# RK3399-AP register map
File version: 1
CPU: CA7 r0p1, little endian, MPU, FPU, I-cache, D-cache, VTOR, 4 interrupt priority bits, 32 interrupts
Registers are 32-bit, read-write, reset 0x0 unless marked. A register's access mark holds for its fields unless they carry their own. Offsets are from the block's base; [hi:lo] are bit positions; {n}, {i} and the like mark numbered series.

## PMUSGRF
Base 0xFF330000
{0x0+4i} ddr_rgn_con{i} access not given (i=0..21)
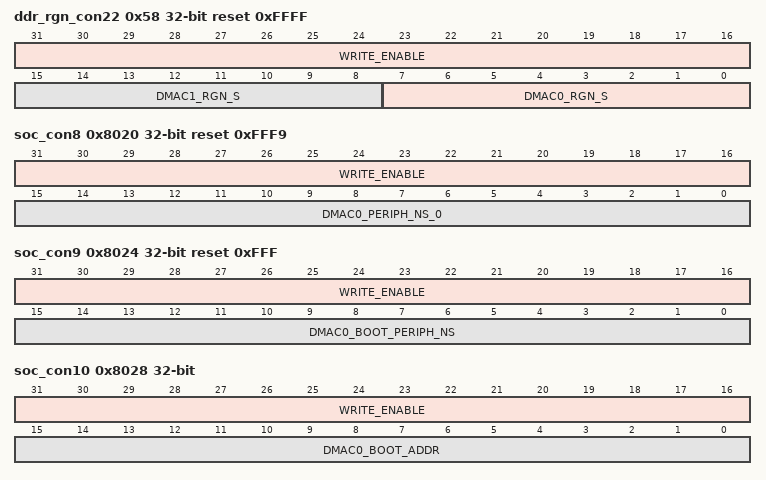
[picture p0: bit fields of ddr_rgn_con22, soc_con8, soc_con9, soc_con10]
0x58 ddr_rgn_con22 access per field reset 0xFFFF
  [31:16] WRITE_ENABLE wo
  [15:8] DMAC1_RGN_S rw — 1 indicates secure, 0 indicates non-secure.
  [7:0] DMAC0_RGN_S rw — 1 indicates secure, 0 indicates non-secure.
{0x0+4i} ddr_rgn_con{i} access not given (i=23..34)
0x8020 soc_con8 access per field reset 0xFFF9
  [31:16] WRITE_ENABLE wo
  [15:0] DMAC0_PERIPH_NS_0 rw — CFG_NS
0x8024 soc_con9 access per field reset 0xFFF
  [31:16] WRITE_ENABLE wo
  [15:0] DMAC0_BOOT_PERIPH_NS rw — 0 indicates secure, 1 indicates non-secure.
0x8028 soc_con10 access per field
  [31:16] WRITE_ENABLE wo
  [15:0] DMAC0_BOOT_ADDR rw — 0 indicates secure, 1 indicates non-secure.
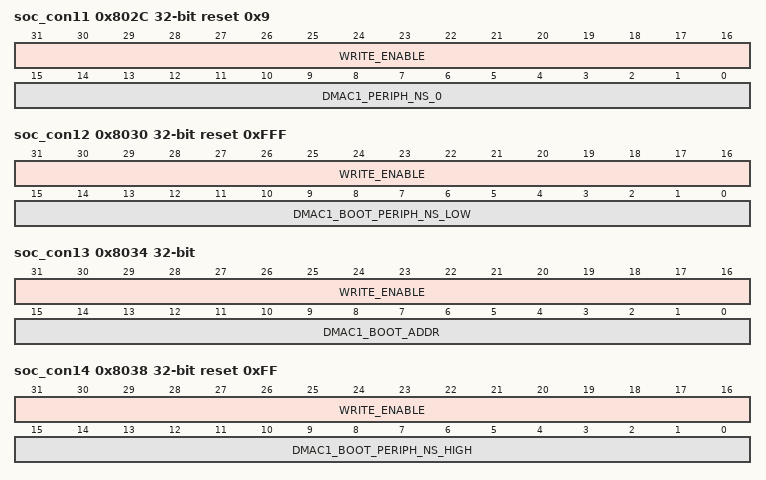
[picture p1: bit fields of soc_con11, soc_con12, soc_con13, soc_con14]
0x802C soc_con11 access per field reset 0x9
  [31:16] WRITE_ENABLE wo
  [15:0] DMAC1_PERIPH_NS_0 rw — (CFG)
0x8030 soc_con12 access per field reset 0xFFF
  [31:16] WRITE_ENABLE wo
  [15:0] DMAC1_BOOT_PERIPH_NS_LOW rw — 0 indicates secure, 1 indicates non-secure.
0x8034 soc_con13 access per field
  [31:16] WRITE_ENABLE wo
  [15:0] DMAC1_BOOT_ADDR rw — 0 indicates secure, 1 indicates non-secure.
0x8038 soc_con14 access per field reset 0xFF
  [31:16] WRITE_ENABLE wo
  [15:0] DMAC1_BOOT_PERIPH_NS_HIGH rw — 0 indicates secure, 1 indicates non-secure.
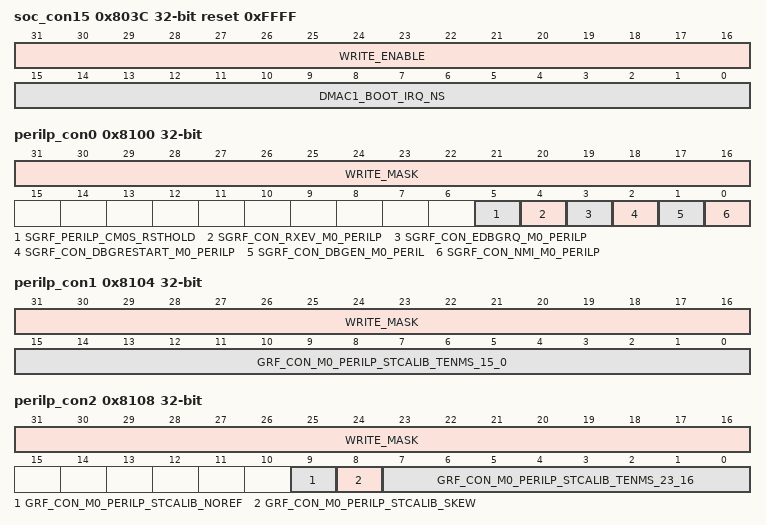
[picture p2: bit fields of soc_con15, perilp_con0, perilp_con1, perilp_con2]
0x803C soc_con15 access per field reset 0xFFFF
  [31:16] WRITE_ENABLE wo
  [15:0] DMAC1_BOOT_IRQ_NS rw — 0 indicates secure, 1 indicates non-secure.
{0x8000+4i} soc_con{i} access not given (i=19..22)
0x8100 perilp_con0 access per field
  [31:16] WRITE_MASK wo
  [5] SGRF_PERILP_CM0S_RSTHOLD rw — Reset hold control
  [4] SGRF_CON_RXEV_M0_PERILP rw — A HIGH level on this input causes the architecture defined Event Register to be set in the Cortex-M0 processor. This causes a WFE instruction to complete. It also awakens the processor if it is sleeping as the result of encountering a WFE instruction when the Event Register is clear.
  [3] SGRF_CON_EDBGRQ_M0_PERILP rw — External debug request
  [2] SGRF_CON_DBGRESTART_M0_PERILP rw — External restart request
  [1] SGRF_CON_DBGEN_M0_PERIL rw — Serial Wire Debug enable
  [0] SGRF_CON_NMI_M0_PERILP rw — Non maskable interrupt
0x8104 perilp_con1 access per field
  [31:16] WRITE_MASK wo
  [15:0] GRF_CON_M0_PERILP_STCALIB_TENMS_15_0 rw — See also: grf_con_m0_perilp_stcalib_tenms_23_16
0x8108 perilp_con2 access per field
  [31:16] WRITE_MASK wo
  [9] GRF_CON_M0_PERILP_STCALIB_NOREF rw — Indicates that no alternative reference clock source has been integrated. Tie HIGH if STCLKEN has been tied off.
  [8] GRF_CON_M0_PERILP_STCALIB_SKEW rw — Tie this LOW if the system timer clock, the external reference clock, or SCLK as indicated by STCALIB[25] (grf_con_m0_perilp_stcalib_noref), can guarantee an exact multiple of 10ms. Otherwise, tie this signal HIGH.
  [7:0] GRF_CON_M0_PERILP_STCALIB_TENMS_23_16 rw — See also: grf_con_m0_perilp_stcalib_tenms_15_0
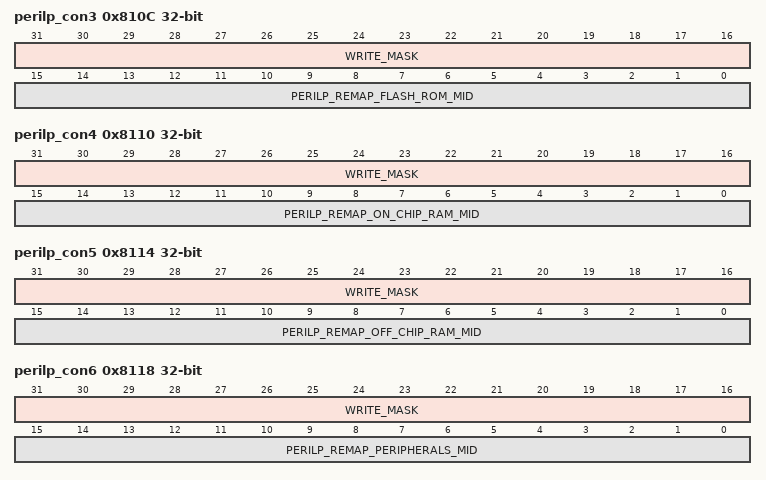
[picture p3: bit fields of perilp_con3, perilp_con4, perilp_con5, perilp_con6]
0x810C perilp_con3 access per field
  [31:16] WRITE_MASK wo
  [15:0] PERILP_REMAP_FLASH_ROM_MID rw — middle 16 bits of 0x00000000-0x1FFFFFFF remap
0x8110 perilp_con4 access per field
  [31:16] WRITE_MASK wo
  [15:0] PERILP_REMAP_ON_CHIP_RAM_MID rw — middle 16 bits of 0x20000000-0x3FFFFFFF remap
0x8114 perilp_con5 access per field
  [31:16] WRITE_MASK wo
  [15:0] PERILP_REMAP_OFF_CHIP_RAM_MID rw — Middle 16 bits of 0x60000000-0x7FFFFFFF and 0x80000000-0x9FFFFFFF memory regions.
0x8118 perilp_con6 access per field
  [31:16] WRITE_MASK wo
  [15:0] PERILP_REMAP_PERIPHERALS_MID rw — middle 16 bits of 0xA0000000-0xDFFFFFFF remap.
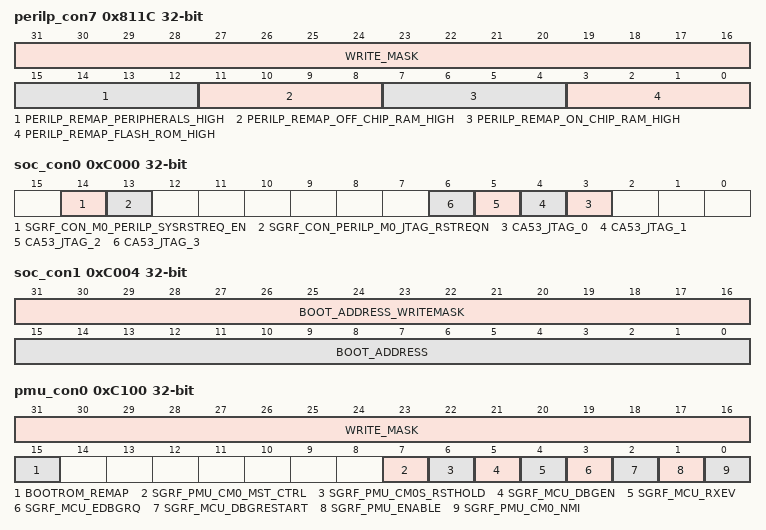
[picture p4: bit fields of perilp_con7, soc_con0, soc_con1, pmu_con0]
0x811C perilp_con7 access per field
  [31:16] WRITE_MASK wo
  [15:12] PERILP_REMAP_PERIPHERALS_HIGH rw — top 4 bits of 0xA0000000-0xDFFFFFFF remap
  [11:8] PERILP_REMAP_OFF_CHIP_RAM_HIGH rw — Top 4 bits of 0x60000000-0x7FFFFFFF and 0x80000000-0x9FFFFFFF memory regions.
  [7:4] PERILP_REMAP_ON_CHIP_RAM_HIGH rw — top 4 bits of 0x20000000-0x3FFFFFFF remap
  [3:0] PERILP_REMAP_FLASH_ROM_HIGH rw — top 4 bits of 0x00000000-0x1FFFFFFF remap
0x8120 perilp_con8
  [7:0] GRF_CON_M0_PERILP_IRQLATENCY — Minimum number of cycles between an interrupt that becomes pended in the NVIC, and the vector fetch for that interrupt being issued
0x8140 perilp_status access not given
0xC000 soc_con0
  [14] SGRF_CON_M0_PERILP_SYSRSTREQ_EN — Enable for SYSRESETREQ
  [13] SGRF_CON_PERILP_M0_JTAG_RSTREQN — Always be 0
  [n+3] CA53_JTAG_{n} (n=0..3) — CA53 JTAG
0xC004 soc_con1 access per field
  [31:16] BOOT_ADDRESS_WRITEMASK wo
  [15:0] BOOT_ADDRESS rw — Warm boot address for CPU. Could be DMAC0 BOOT ADDR
0xC100 pmu_con0 access per field
  [31:16] WRITE_MASK wo
  [15] BOOTROM_REMAP rw — Remaps 0xFFFF0000 to BOOTROM or INTMEM0. From page 29. **NOTE**: might be bootrom_remap_shadow instead.
  [7] SGRF_PMU_CM0_MST_CTRL rw — Master security attribute
  [6] SGRF_PMU_CM0S_RSTHOLD rw — Reset hold control
  [5] SGRF_MCU_DBGEN rw — Serial Wire Debug enable
  [4] SGRF_MCU_RXEV rw — A HIGH level on this input causes the architecture defined Event Register to be set in the Cortex-M0 processor. This causes a WFE instruction to complete. It also awakens the processor if it is sleeping as the result of encountering a WFE instruction when the Event Register is clear.
  [3] SGRF_MCU_EDBGRQ rw — External debug request
  [2] SGRF_MCU_DBGRESTART rw — External restart request
  [1] SGRF_PMU_ENABLE rw — Internal PMU enable
  [0] SGRF_PMU_CM0_NMI rw — Non maskable interrupt
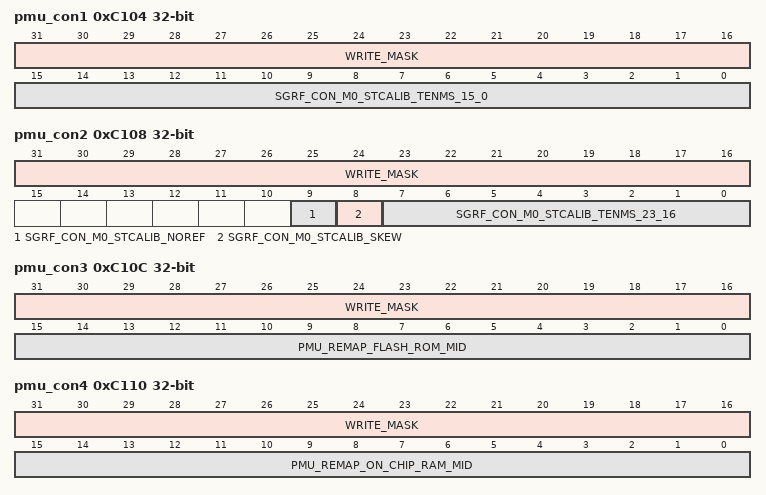
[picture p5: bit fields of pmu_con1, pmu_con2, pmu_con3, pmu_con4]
0xC104 pmu_con1 access per field
  [31:16] WRITE_MASK wo
  [15:0] SGRF_CON_M0_STCALIB_TENMS_15_0 rw — See also: sgrf_con_m0_stcalib_tenms_23_16
0xC108 pmu_con2 access per field
  [31:16] WRITE_MASK wo
  [9] SGRF_CON_M0_STCALIB_NOREF rw — Indicates that no alternative reference clock source has been integrated. Tie HIGH if STCLKEN has been tied off.
  [8] SGRF_CON_M0_STCALIB_SKEW rw — Tie this LOW if the system timer clock, the external reference clock, or SCLK as indicated by STCALIB[25] (sgrf_con_m0_stcalib_noref), can guarantee an exact multiple of 10ms. Otherwise, tie this signal HIGH.
  [7:0] SGRF_CON_M0_STCALIB_TENMS_23_16 rw — See also: sgrf_con_m0_stcalib_tenms_15_0
0xC10C pmu_con3 access per field
  [31:16] WRITE_MASK wo
  [15:0] PMU_REMAP_FLASH_ROM_MID rw — middle 16 bits of 0x00000000-0x1FFFFFFF remap
0xC110 pmu_con4 access per field
  [31:16] WRITE_MASK wo
  [15:0] PMU_REMAP_ON_CHIP_RAM_MID rw — middle 16 bits of 0x20000000-0x3FFFFFFF remap
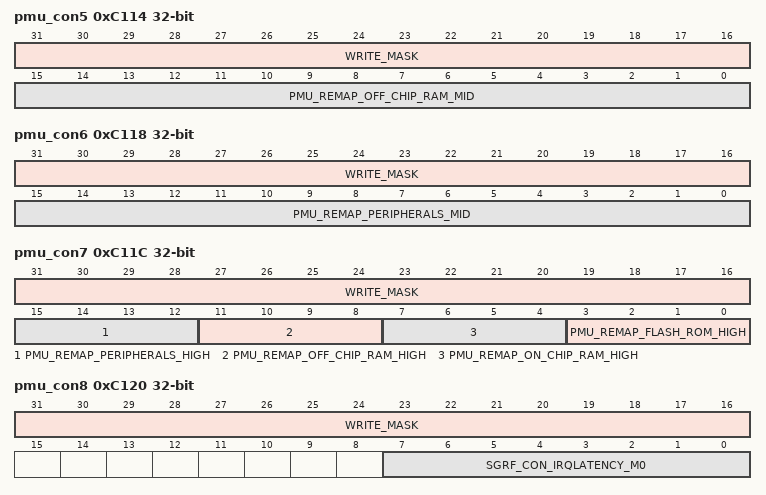
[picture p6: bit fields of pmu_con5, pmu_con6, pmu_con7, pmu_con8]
0xC114 pmu_con5 access per field
  [31:16] WRITE_MASK wo
  [15:0] PMU_REMAP_OFF_CHIP_RAM_MID rw — Middle 16 bits of 0x60000000-0x7FFFFFFF and 0x80000000-0x9FFFFFFF memory regions.
0xC118 pmu_con6 access per field
  [31:16] WRITE_MASK wo
  [15:0] PMU_REMAP_PERIPHERALS_MID rw — middle 16 bits of 0xA0000000-0xDFFFFFFF remap
0xC11C pmu_con7 access per field
  [31:16] WRITE_MASK wo
  [15:12] PMU_REMAP_PERIPHERALS_HIGH rw — top 4 bits of 0xA0000000-0xDFFFFFFF remap
  [11:8] PMU_REMAP_OFF_CHIP_RAM_HIGH rw — Top 4 bits of 0x60000000-0x7FFFFFFF and 0x80000000-0x9FFFFFFF memory regions.
  [7:4] PMU_REMAP_ON_CHIP_RAM_HIGH rw — top 4 bits of 0x20000000-0x3FFFFFFF remap
  [3:0] PMU_REMAP_FLASH_ROM_HIGH rw — top 4 bits of 0x00000000-0x1FFFFFFF remap
0xC120 pmu_con8 access per field
  [31:16] WRITE_MASK wo
  [7:0] SGRF_CON_IRQLATENCY_M0 rw — Minimum number of cycles between an interrupt that becomes pended in the NVIC, and the vector fetch for that interrupt being issued
0xC180 fast_boot_addr access not given
0xC200 efuse_prg_mask access not given
0xC204 efuse_read_mask access not given
0xC240 pmu_slv_con0 access not given
0xC244 pmu_slv_con1 access not given
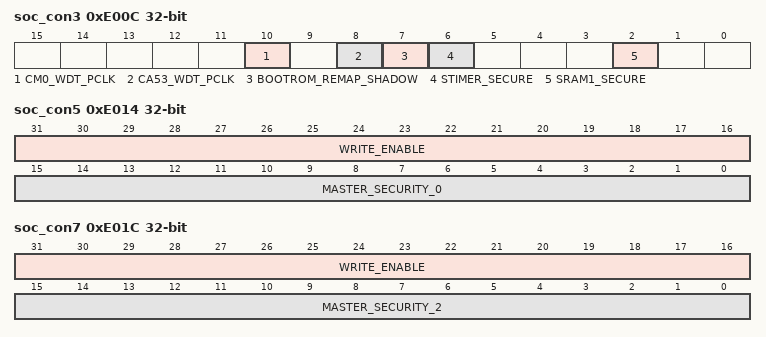
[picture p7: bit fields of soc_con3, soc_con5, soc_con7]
0xE00C soc_con3
  [10] CM0_WDT_PCLK
  [8] CA53_WDT_PCLK
  [7] BOOTROM_REMAP_SHADOW — Remaps 0xFFFF0000 to BOOTROM or INTMEM0. From page 892. **NOTE**: might be bootrom_remap instead.
  [6] STIMER_SECURE
  [2] SRAM1_SECURE — pmusram (SRAM1) secure
0xE010 soc_con4
  [9:0] TZMA_SIZE — Controls the region considered secure by the TZMA (TrustZone Memory Adapter). See p990 of the TRM Part 1. Secure region size is set in 4KB increments, from 0KB to 192KB.
0xE014 soc_con5 access per field
  [31:16] WRITE_ENABLE wo — Write 1 to enable writing to bit in lower 16 bits.
  [15:0] MASTER_SECURITY_0 rw
0xE018 soc_con6 access per field reset 0x2000
  [31:16] WRITE_ENABLE wo — Write 1 to enable writing to bit in lower 16 bits.
  [13] SGRF_CON_PERIM0_SECURE_CTRL rw — Master security attribute
  [15:0] MASTER_SECURITY_1 rw
0xE01C soc_con7 access per field
  [31:16] WRITE_ENABLE wo — Write 1 to enable writing to bit in lower 16 bits.
  [15:0] MASTER_SECURITY_2 rw
{0xE000+4i} soc_con{i} access not given (i=16..18)
0xE3C0 slv_secure_con0 access not given
0xE3C4 slv_secure_con1 access not given
{0xE3C4+4i} slv_secure_con{i} access not given (i=2..4)
